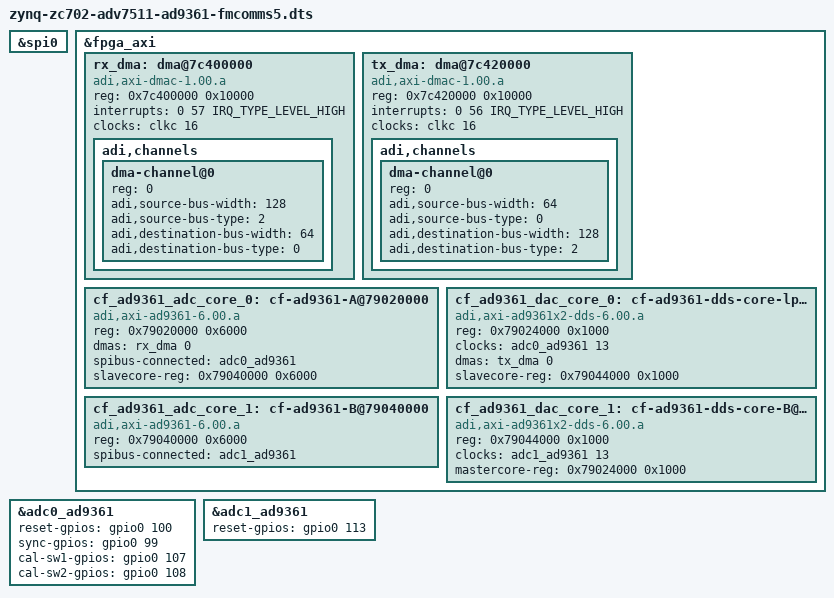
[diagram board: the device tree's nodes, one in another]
/dts-v1/;

#include "zynq-zc702.dtsi"
#include "zynq-zc702-adv7511.dtsi"

&spi0 {
	status = "okay";
};

#define fmc_spi spi0

&fpga_axi {
	rx_dma: dma@7c400000 {
		compatible = "adi,axi-dmac-1.00.a";
		reg = <0x7c400000 0x10000>;
		#dma-cells = <1>;
		interrupts = <0 57 IRQ_TYPE_LEVEL_HIGH>;
		clocks = <&clkc 16>;

		adi,channels {
			#size-cells = <0>;
			#address-cells = <1>;

			dma-channel@0 {
				reg = <0>;
				adi,source-bus-width = <128>;
				adi,source-bus-type = <2>;
				adi,destination-bus-width = <64>;
				adi,destination-bus-type = <0>;
			};
		};
	};

	tx_dma: dma@7c420000 {
		compatible = "adi,axi-dmac-1.00.a";
		reg = <0x7c420000 0x10000>;
		#dma-cells = <1>;
		interrupts = <0 56 IRQ_TYPE_LEVEL_HIGH>;
		clocks = <&clkc 16>;

		adi,channels {
			#size-cells = <0>;
			#address-cells = <1>;

			dma-channel@0 {
				reg = <0>;
				adi,source-bus-width = <64>;
				adi,source-bus-type = <0>;
				adi,destination-bus-width = <128>;
				adi,destination-bus-type = <2>;
			};
		};
	};

	/* Master HDL core with DMA */
	cf_ad9361_adc_core_0: cf-ad9361-A@79020000 {
		compatible = "adi,axi-ad9361-6.00.a";
		reg = <0x79020000 0x6000>;
		dmas = <&rx_dma 0>;
		dma-names = "rx";
		spibus-connected = <&adc0_ad9361>;
		slavecore-reg = <0x79040000 0x6000>;
	};

	cf_ad9361_dac_core_0: cf-ad9361-dds-core-lpc@79024000 {
		compatible = "adi,axi-ad9361x2-dds-6.00.a";
		reg = <0x79024000 0x1000>;
		clocks = <&adc0_ad9361 13>;
		clock-names = "sampl_clk";
		dmas = <&tx_dma 0>;
		dma-names = "tx";
		slavecore-reg = <0x79044000 0x1000>;
	};

	/* Slave HDL core without DMA */
	cf_ad9361_adc_core_1: cf-ad9361-B@79040000 {
		compatible = "adi,axi-ad9361-6.00.a";
		reg = <0x79040000 0x6000>;
		spibus-connected = <&adc1_ad9361>;
	};

	cf_ad9361_dac_core_1: cf-ad9361-dds-core-B@79044000 {
		compatible = "adi,axi-ad9361x2-dds-6.00.a";
		reg = <0x79044000 0x1000>;
		clocks = <&adc1_ad9361 13>;
		clock-names = "sampl_clk";
		mastercore-reg = <0x79024000 0x1000>;
	};
};

#include "adi-fmcomms5.dtsi"

&adc0_ad9361 {
	reset-gpios = <&gpio0 100 0>;
	sync-gpios = <&gpio0 99 0>;
	cal-sw1-gpios = <&gpio0 107 0>;
	cal-sw2-gpios = <&gpio0 108 0>;
};

&adc1_ad9361 {
	reset-gpios = <&gpio0 113 0>;
};
